AUTOSAR XML (schema 00044)
package /ComponentTypes
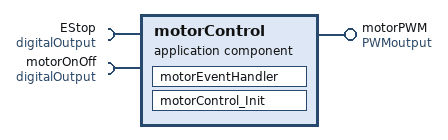
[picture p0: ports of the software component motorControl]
  application sw component type motorControl
    provide port motorPWM: provided-com-specs=[dutyCycle, windowLevel], provided-interface=PWMoutput
    require port EStop: nonqueued-receiver-com-spec=data-element=outputStatus, required-interface=digitalOutput
    require port motorOnOff: nonqueued-receiver-com-spec=data-element=outputStatus, required-interface=digitalOutput
    behavior motorControl_InternalBehavior
      init event motorControl_InitEvent: start-on-event=motorControl_Init
      data received event DRT_Runnable_EStop_outputStatus: start-on-event=motorEventHandler, data=EStop.outputStatus
      data received event DRT_Runnable_motorOnOff_outputStatus: start-on-event=motorEventHandler, data=motorOnOff.outputStatus
      runnable motorEventHandler
        data-receive-point-by-values:
          access REC_EStop_outputStatus: accessed-variable=EStop.outputStatus
          access REC_motorOnOff_outputStatus: accessed-variable=motorOnOff.outputStatus
        data-send-points:
          access SEND_motorPWM_dutyCycle: accessed-variable=motorPWM.dutyCycle
      runnable motorControl_Init
        data-send-points:
          access SEND_motorPWM_dutyCycle: accessed-variable=motorPWM.dutyCycle
  swc implementation motorControl_Implementation: behavior=motorControl_InternalBehavior
